# SF32LB58x register map
File version: 1.0
CPU: CM33 r0p1, little endian, MPU, FPU, 3 interrupt priority bits
Registers are 32-bit, read-write, reset 0x0 unless marked. A register's access mark holds for its fields unless they carry their own. Offsets are from the block's base; [hi:lo] are bit positions; 'fields as' and 'values as' point back to an identical list.

## DSI_HOST
Base 0x4001E000
0x00 VER
  [31:0] VALUE
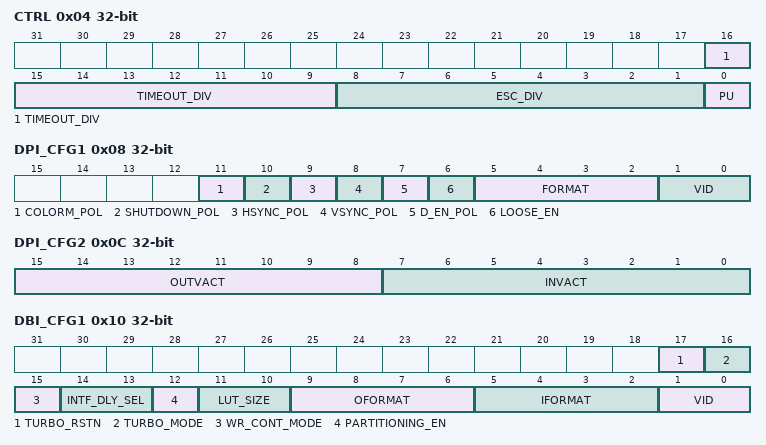
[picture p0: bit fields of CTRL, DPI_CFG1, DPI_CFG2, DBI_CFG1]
0x04 CTRL
  [16:9] TIMEOUT_DIV — Time out clock divider
  [8:1] ESC_DIV — tx escape clock divider
  [0] PU — 0: Reset 1: Power-up
0x08 DPI_CFG1
  [11] COLORM_POL — color mode polarity
  [10] SHUTDOWN_POL — shutdown polarity
  [9] HSYNC_POL — hsync polarity
  [8] VSYNC_POL — vsync polarity
  [7] D_EN_POL — data enable polarity
  [6] LOOSE_EN — enable loosely packed variant to 18-bit mode
  [5:2] FORMAT — dpi color format 4'b0000: 16-bit configuration 1 4'b0001: 16-bit configuration 2 4'b0010: 16-bit configuration 3 4'b0011: 18-bit configuration 1 4'b0100: 18-bit configuration 2 4'b0101: 24-bit 4'b0110: 20-bit YCbCr 4:2:2 loosely packed 4'b0111: 24-bit YCbCr 4:2:2 4'b1000: 16-bit YCbCr 4:2:2 4'b1001: 30-bit 4'b1010: 36-bit 4'b1011-1111: 12-bit YCbCr 4:2:0
  [1:0] VID — dpi channel id
0x0C DPI_CFG2
  [15:8] OUTVACT — command packet size in a line during VSA/VBP/VFP region
  [7:0] INVACT — command packet size in a line during VACT region
0x10 DBI_CFG1
  [17] TURBO_RSTN — dbi turbo mode engine resetn
  [16] TURBO_MODE — dbi turbo mode 1: turbo mode, dbi bandwidth can reach lanebyteclk*8 bps 0: normal mode
  [15] WR_CONT_MODE — dbi write memory continuous mode when internal auto partioning enable. 1: write memory continue command(0x3c) can initial data transfer. 0: write memory continue command(0x3c) cannot initial data transfer.
  [14:13] INTF_DLY_SEL — dbi interface data delay select 00: no delay 01: delay by half cycle 10,11: delay by one cycle
  [12] PARTITIONING_EN — external partitioning enable 1: external partitioning enable 0: internal auto partitioning enable
  [11:10] LUT_SIZE — LUT commands size 00,11: 16-bit color display 01: 18-bit color display 10: 24-bit color display
  [9:6] OFORMAT — DBI output pixel format 0000: 8-bit 8 bpp 0001: 8-bit 12 bpp 0010: 8-bit 16 bpp 0011: 8-bit 18 bpp 0100: 8-bit 24 bpp 0101: 9-bit 18 bpp 0110: 16-bit 8 bpp 0111: 16-bit 12 bpp 1000: 16-bit 16 bpp 1001: 16-bit 18 bpp, option 1 1010: 16-bit 18 bpp, option 2 1011: 16-bit 24 bpp, option 1 1100: 16-bit 24 bpp, option 2
  [5:2] IFORMAT — DBI input pixel format 0000: 8-bit 8 bpp 0001: 8-bit 12 bpp 0010: 8-bit 16 bpp 0011: 8-bit 18 bpp 0100: 8-bit 24 bpp 0101: 9-bit 18 bpp 0110: 16-bit 8 bpp 0111: 16-bit 12 bpp 1000: 16-bit 16 bpp 1001: 16-bit 18 bpp, option 1 1010: 16-bit 18 bpp, option 2 1011: 16-bit 24 bpp, option 1 1100: 16-bit 24 bpp, option 2
  [1:0] VID — DBI virtual channel id
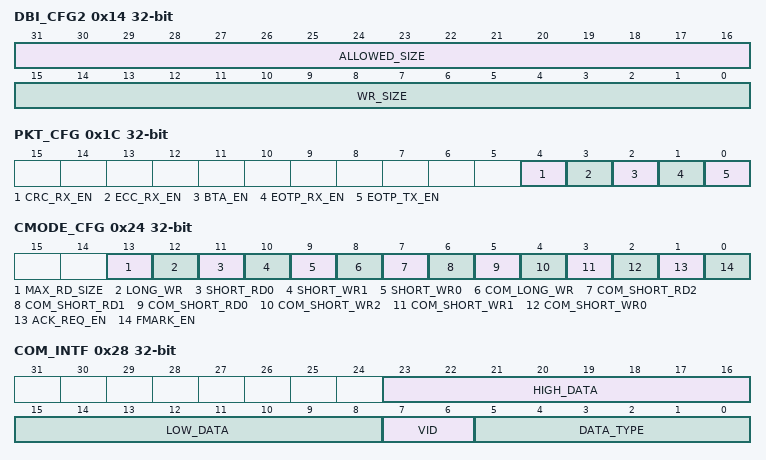
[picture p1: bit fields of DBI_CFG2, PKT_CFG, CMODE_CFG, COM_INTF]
0x14 DBI_CFG2
  [31:16] ALLOWED_SIZE — maximum allowed write memory data size. Used when partioning is enable.
  [15:0] WR_SIZE — write memory data size. DSI packet payload is the actual payload size minus 1
0x18 COM_CFG
  [1:0] VID — common interface virtual channel id
0x1C PKT_CFG
  [4] CRC_RX_EN — CRC reception enable
  [3] ECC_RX_EN — ECC reception enable
  [2] BTA_EN — bus turn around request
  [1] EOTP_RX_EN — EoTp reception
  [0] EOTP_TX_EN — EoTp transmission
0x20 MODE_CFG reset 0x1
  [0] CMD_VIDEO_SEL — 0: video mode 1: command mode
0x24 CMODE_CFG
  [13] MAX_RD_SIZE — maximum read packet size command transmission type 0: high-speed 1: low-power
  [12] LONG_WR — DCS long write packet command transmission type 0: high-speed 1: low-power
  [11] SHORT_RD0 — DCS short read packet with 0 parameter command transmission type 0: high-speed 1: low-power
  [10] SHORT_WR1 — DCS short write packet with 1 parameter command transmission type 0: high-speed 1: low-power
  [9] SHORT_WR0 — DCS short write packet with 0 parameter command transmission type 0: high-speed 1: low-power
  [8] COM_LONG_WR — generic long write packet command transmission type 0: high-speed 1: low-power
  [7] COM_SHORT_RD2 — common short read with 2 paramters command transmission type 0: high-speed 1: low-power
  [6] COM_SHORT_RD1 — common short read with 1 paramters command transmission type 0: high-speed 1: low-power
  [5] COM_SHORT_RD0 — common short read with 0 paramters command transmission type 0: high-speed 1: low-power
  [4] COM_SHORT_WR2 — common short write with 2 paramters command transmission type 0: high-speed 1: low-power
  [3] COM_SHORT_WR1 — common short write with 1 paramters command transmission type 0: high-speed 1: low-power
  [2] COM_SHORT_WR0 — common short write with 0 paramters command transmission type 0: high-speed 1: low-power
  [1] ACK_REQ_EN — acknowledge request enable
  [0] FMARK_EN — fmark enable
0x28 COM_INTF
  [23:16] HIGH_DATA — common interface MSB of header packet's word count of long packet or data 1 for short packets
  [15:8] LOW_DATA — common interface LSB of header packet's word count of long packet or data 0 for short packets
  [7:6] VID — common interface virtual channel id
  [5:0] DATA_TYPE — common interface packet data type
0x2C COM_PLD
  [31:0] PDATA — common interface payload data
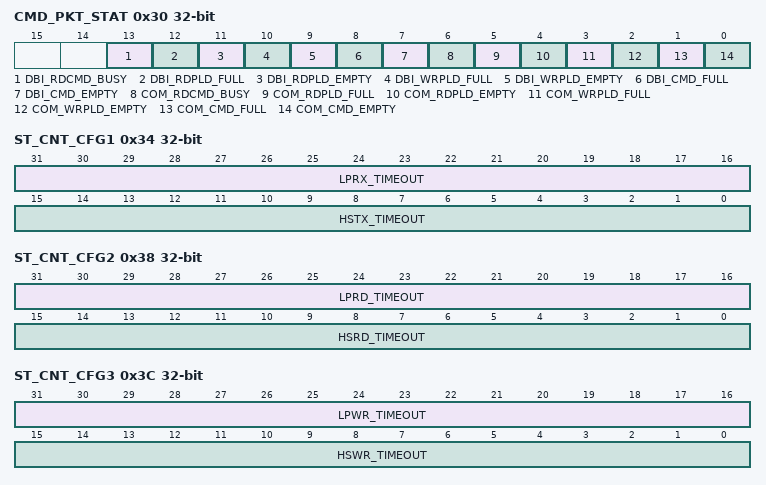
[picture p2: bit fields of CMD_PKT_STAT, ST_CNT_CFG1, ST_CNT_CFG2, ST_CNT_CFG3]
0x30 CMD_PKT_STAT
  [13] DBI_RDCMD_BUSY — DBI read command busy
  [12] DBI_RDPLD_FULL — DBI read payload FIFO full
  [11] DBI_RDPLD_EMPTY — DBI read payload FIFO empty
  [10] DBI_WRPLD_FULL — DBI write payload FIFO full
  [9] DBI_WRPLD_EMPTY — DBI write payload FIFO empty
  [8] DBI_CMD_FULL — DBI command FIFO full
  [7] DBI_CMD_EMPTY — DBI command FIFO empty
  [6] COM_RDCMD_BUSY — common read command busy
  [5] COM_RDPLD_FULL — common read payload FIFO full
  [4] COM_RDPLD_EMPTY — common read payload FIFO empty
  [3] COM_WRPLD_FULL — common write payload FIFO full
  [2] COM_WRPLD_EMPTY — common write payload FIFO empty
  [1] COM_CMD_FULL — common command FIFO full
  [0] COM_CMD_EMPTY — common command FIFO empty
0x34 ST_CNT_CFG1
  [31:16] LPRX_TIMEOUT — LPRX timeout counter
  [15:0] HSTX_TIMEOUT — HSTX timeout counter
0x38 ST_CNT_CFG2
  [31:16] LPRD_TIMEOUT — LP read timeout counter
  [15:0] HSRD_TIMEOUT — HS read timeout counter
0x3C ST_CNT_CFG3
  [31:16] LPWR_TIMEOUT — LP write timeout counter
  [15:0] HSWR_TIMEOUT — HS write timeout counter
0x40 ST_CNT_CFG4
  [15:0] BTA_TIMEOUT — BTA timeout counter
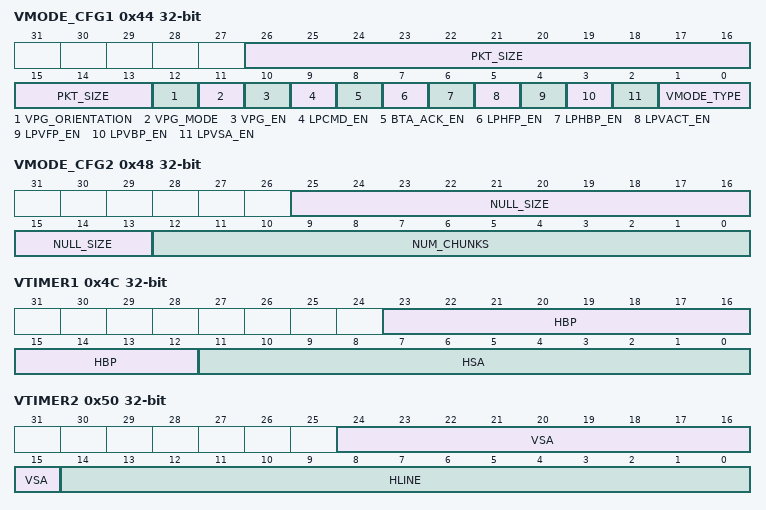
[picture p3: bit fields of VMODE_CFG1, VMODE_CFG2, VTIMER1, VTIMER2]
0x44 VMODE_CFG1
  [26:13] PKT_SIZE — Number of pixels in a single video packet
  [12] VPG_ORIENTATION — color bar orientation 0: vertical mode 1: horizontal mode
  [11] VPG_MODE — pattern 0: color bar 1: ber pattern
  [10] VPG_EN — video mode pattern generator enable
  [9] LPCMD_EN — enable command transmission only in lp mode
  [8] BTA_ACK_EN — enable request for an ack response
  [7] LPHFP_EN — enable return to lp inside HFP
  [6] LPHBP_EN — enable return to lp inside HBP
  [5] LPVACT_EN — enable return to lp inside VACT
  [4] LPVFP_EN — enable return to lp inside VFP
  [3] LPVBP_EN — enable return to lp inside VBP
  [2] LPVSA_EN — enable return to lp inside VSA
  [1:0] VMODE_TYPE — indicates video mode transmission type 00: Non-burst with sync pulses 01: Non-burst with sync events 10,11: Burst mode
0x48 VMODE_CFG2
  [25:13] NULL_SIZE — number of bytes inside a null packet
  [12:0] NUM_CHUNKS — number of chunks during a Line period
0x4C VTIMER1
  [23:12] HBP — HBP period
  [11:0] HSA — HSA period
0x50 VTIMER2
  [24:15] VSA — VSA lines
  [14:0] HLINE — HLINE period
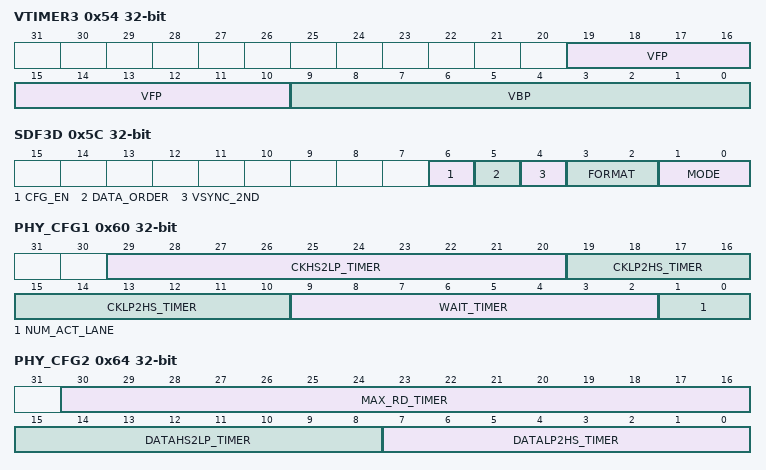
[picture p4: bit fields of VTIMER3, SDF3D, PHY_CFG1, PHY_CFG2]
0x54 VTIMER3
  [19:10] VFP — VFP lines
  [9:0] VBP — VBP lines
0x58 VTIMER4
  [13:0] VACT — VACTIVE lines
0x5C SDF3D
  [6] CFG_EN — transfer packet with 3D control payload
  [5] DATA_ORDER — data order 0: left eye data first 1: right eye data first
  [4] VSYNC_2ND — set sync between left and right image 0: no vsync pulse 1: add sync pulse
  [3:2] FORMAT — 3D image format 00: Line 01: Frame 10: Pixel 11: Reserved
  [1:0] MODE — 3D mode 00: 3D mode off 01: 3D mode on, portrait orientation 10: 3D mode on, landscape orientation 11: Reserved
0x60 PHY_CFG1
  [29:20] CKHS2LP_TIMER — CK lane HS to LP transition time
  [19:10] CKLP2HS_TIMER — CK lane LP to HS transition time
  [9:2] WAIT_TIMER — wait period between Stop State and HS
  [1:0] NUM_ACT_LANE — Number of active lanes 00: 1 data lane 01: 2 data lane 10,11: Reserved
0x64 PHY_CFG2
  [30:16] MAX_RD_TIMER — max read time
  [15:8] DATAHS2LP_TIMER — Data lane HS to LP transition time
  [7:0] DATALP2HS_TIMER — Data lane LP to HS transition time
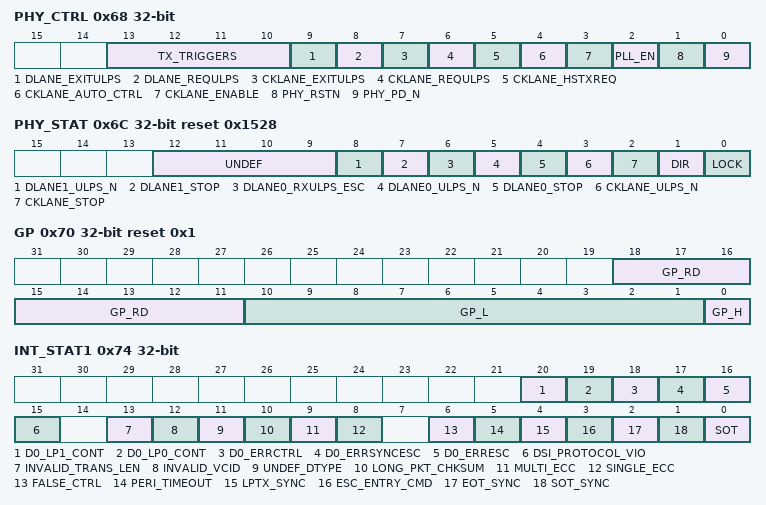
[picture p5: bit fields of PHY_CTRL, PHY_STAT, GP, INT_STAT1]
0x68 PHY_CTRL
  [13:10] TX_TRIGGERS — tx trigger transmission
  [9] DLANE_EXITULPS — ULPS exit for all data lane
  [8] DLANE_REQULPS — ULPS request for all data lane
  [7] CKLANE_EXITULPS — ULPS exit for ck lane
  [6] CKLANE_REQULPS — ULPS request for ck lane
  [5] CKLANE_HSTXREQ — hstx request for ck lane
  [4] CKLANE_AUTO_CTRL — ck lane auto on/off control
  [3] CKLANE_ENABLE
  [2] PLL_EN — pll enable
  [1] PHY_RSTN — D_PHY reset, active low
  [0] PHY_PD_N — D_PHY power down, active low
0x6C PHY_STAT reset 0x1528
  [12:9] UNDEF
  [8] DLANE1_ULPS_N — Data lane 1 ulps active not signal
  [7] DLANE1_STOP — Data lane 1 stop state signal
  [6] DLANE0_RXULPS_ESC — Data lane 0 rx ulps esc signal
  [5] DLANE0_ULPS_N — Data lane 0 ulps active not signal
  [4] DLANE0_STOP — Data lane 0 stop state signal
  [3] CKLANE_ULPS_N — CK lane ulps active not signal
  [2] CKLANE_STOP — CK lane stop state signal
  [1] DIR — phy direction
  [0] LOCK — phy lock
0x70 GP reset 0x1
  [18:11] GP_RD, [10:1] GP_L, [0] GP_H
0x74 INT_STAT1
  [20] D0_LP1_CONT — dlane0 LP1 contention error
  [19] D0_LP0_CONT — dlane0 LP0 contention error
  [18] D0_ERRCTRL — dlane0 ErrControl error
  [17] D0_ERRSYNCESC — dlane0 ErrSyncEsc lpdt synchronization error
  [16] D0_ERRESC — dlane0 ErrEsc escape entry error
  [15] DSI_PROTOCOL_VIO — DSI protocol violation
  [13] INVALID_TRANS_LEN — invalid transmission length
  [12] INVALID_VCID — invalid DSI VC ID
  [11] UNDEF_DTYPE — undefined DSI data type error
  [10] LONG_PKT_CHKSUM — long packet checksum error
  [9] MULTI_ECC — multi-bit ECC error for ack report
  [8] SINGLE_ECC — single-bit ECC error for ack report
  [6] FALSE_CTRL — False Control error
  [5] PERI_TIMEOUT — Peripheral Timeout error
  [4] LPTX_SYNC — LP Transmit Sync error
  [3] ESC_ENTRY_CMD — ESC Mode Entry Command error
  [2] EOT_SYNC — EoT Sync error
  [1] SOT_SYNC — SoT Sync error
  [0] SOT — SoT error
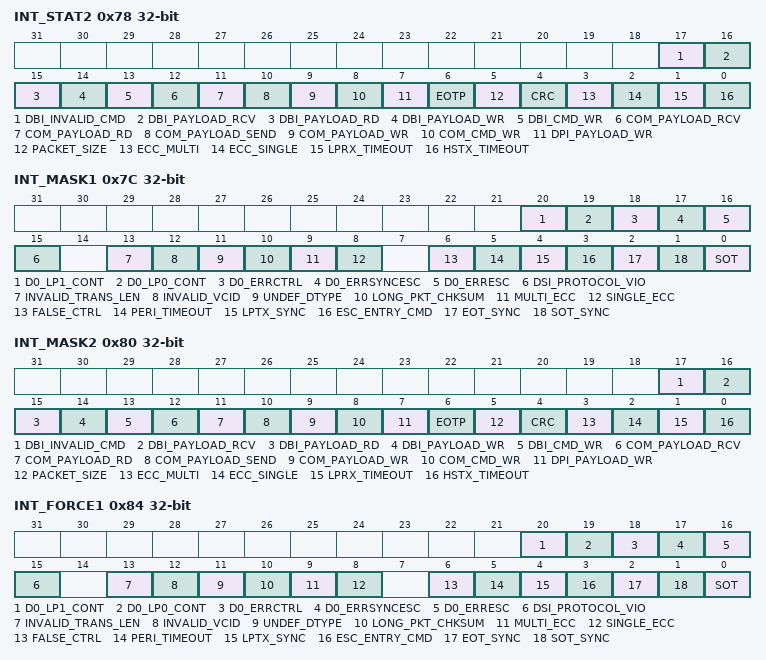
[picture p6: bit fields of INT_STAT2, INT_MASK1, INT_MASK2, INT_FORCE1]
0x78 INT_STAT2
  [17] DBI_INVALID_CMD — dbi invalid command error
  [16] DBI_PAYLOAD_RCV — dbi payload FIFO overflow during packet read back
  [15] DBI_PAYLOAD_RD — dbi payload FIFO underflow during DCS read data
  [14] DBI_PAYLOAD_WR — dbi payload FIFO overflow during data write
  [13] DBI_CMD_WR — dbi command FIFO overflow during command write
  [12] COM_PAYLOAD_RCV — common interface payload FIFO overflow during packet read back
  [11] COM_PAYLOAD_RD — common interface payload FIFO underflow during DCS read data
  [10] COM_PAYLOAD_SEND — common interface payload FIFO underflow during packet build
  [9] COM_PAYLOAD_WR — common interface payload FIFO overflow during data write
  [8] COM_CMD_WR — common interface command FIFO overflow during command write
  [7] DPI_PAYLOAD_WR — dpi payload FIFO overflow
  [6] EOTP — EoTp packet is not received
  [5] PACKET_SIZE — packet size error
  [4] CRC — CRC error in received packet
  [3] ECC_MULTI — ECC multiple error in received packet
  [2] ECC_SINGLE — ECC single error in received packet
  [1] LPRX_TIMEOUT
  [0] HSTX_TIMEOUT
0x7C INT_MASK1
  [20] D0_LP1_CONT, [19] D0_LP0_CONT, [18] D0_ERRCTRL, [17] D0_ERRSYNCESC, [16] D0_ERRESC, [15] DSI_PROTOCOL_VIO, [13] INVALID_TRANS_LEN, [12] INVALID_VCID, [11] UNDEF_DTYPE, [10] LONG_PKT_CHKSUM, [9] MULTI_ECC, [8] SINGLE_ECC, [6] FALSE_CTRL, [5] PERI_TIMEOUT, [4] LPTX_SYNC, [3] ESC_ENTRY_CMD, [2] EOT_SYNC, [1] SOT_SYNC, [0] SOT
0x80 INT_MASK2
  [17] DBI_INVALID_CMD, [16] DBI_PAYLOAD_RCV, [15] DBI_PAYLOAD_RD, [14] DBI_PAYLOAD_WR, [13] DBI_CMD_WR, [12] COM_PAYLOAD_RCV, [11] COM_PAYLOAD_RD, [10] COM_PAYLOAD_SEND, [9] COM_PAYLOAD_WR, [8] COM_CMD_WR, [7] DPI_PAYLOAD_WR, [6] EOTP, [5] PACKET_SIZE, [4] CRC, [3] ECC_MULTI, [2] ECC_SINGLE, [1] LPRX_TIMEOUT, [0] HSTX_TIMEOUT
0x84 INT_FORCE1
  fields as INT_MASK1
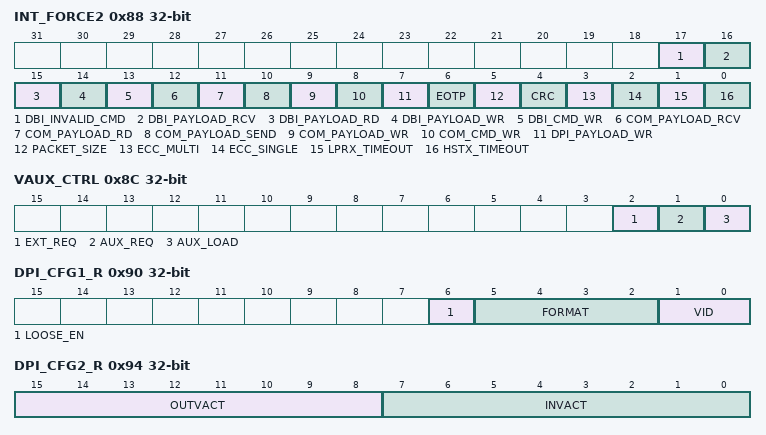
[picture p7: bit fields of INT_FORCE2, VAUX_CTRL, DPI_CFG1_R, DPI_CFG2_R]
0x88 INT_FORCE2
  fields as INT_MASK2
0x8C VAUX_CTRL
  [2] EXT_REQ — When set to 1, the video request is done by external pin. In this mode, aux_req is ignored.
  [1] AUX_REQ — When set to 1, the DPI registers are copied to the auxiliary registers. After copying, this bit is auto cleared.
  [0] AUX_LOAD — When set to 1, DPI receives the active configuration from the auxiliary registers. When this bit is set along with the aux_req bit, the auxiliary registers are automatically updated.
0x90 DPI_CFG1_R
  [6] LOOSE_EN — enable loosely packed variant to 18-bit mode
  [5:2] FORMAT — dpi color format
  [1:0] VID — dpi channel id
0x94 DPI_CFG2_R
  fields as DPI_CFG2
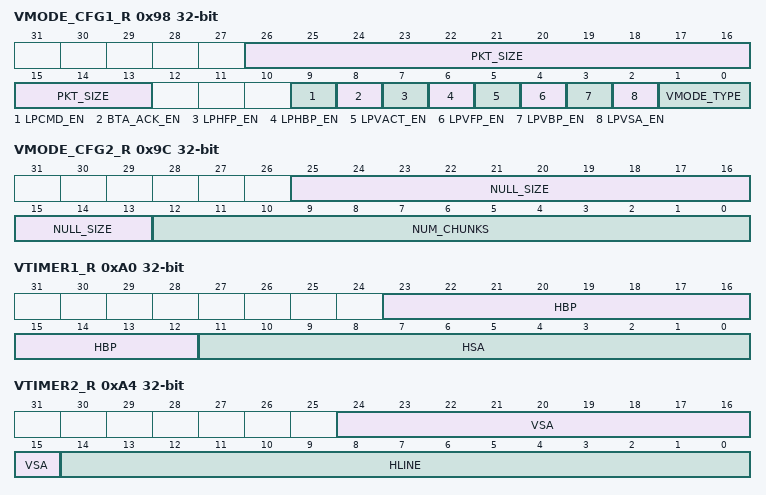
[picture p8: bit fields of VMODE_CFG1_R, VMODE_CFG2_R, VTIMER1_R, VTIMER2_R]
0x98 VMODE_CFG1_R
  [26:13] PKT_SIZE — Number of pixels in a single video packet
  [9] LPCMD_EN — enable command transmission only in lp mode
  [8] BTA_ACK_EN — enable request for an ack response
  [7] LPHFP_EN — enable return to lp inside HFP
  [6] LPHBP_EN — enable return to lp inside HBP
  [5] LPVACT_EN — enable return to lp inside VACT
  [4] LPVFP_EN — enable return to lp inside VFP
  [3] LPVBP_EN — enable return to lp inside VBP
  [2] LPVSA_EN — enable return to lp inside VSA
  [1:0] VMODE_TYPE — indicates video mode transmission type 00: Non-burst with sync pulses 01: Non-burst with sync events 10,11: Burst mode
0x9C VMODE_CFG2_R
  fields as VMODE_CFG2
0xA0 VTIMER1_R
  [23:12] HBP — HBP period
  [11:0] HSA — HSA period
0xA4 VTIMER2_R
  [24:15] VSA — VSA lines
  [14:0] HLINE — HLINE period
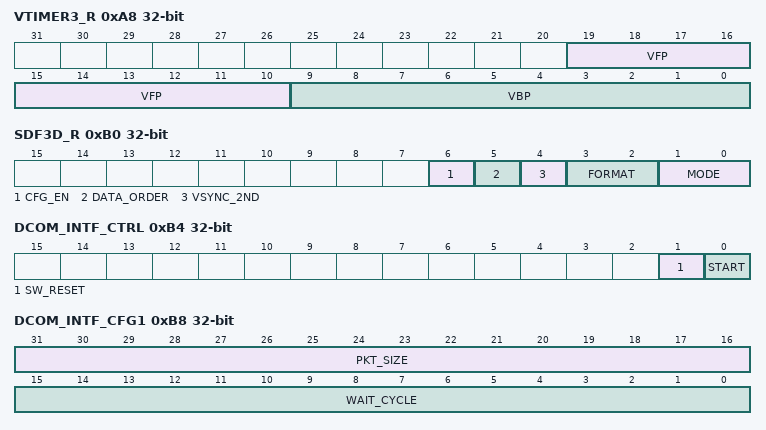
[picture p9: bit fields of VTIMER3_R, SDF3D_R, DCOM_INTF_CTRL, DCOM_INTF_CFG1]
0xA8 VTIMER3_R
  [19:10] VFP — VFP lines
  [9:0] VBP — VBP lines
0xAC VTIMER4_R
  [13:0] VACT — VACTIVE lines
0xB0 SDF3D_R
  fields as SDF3D
0xB4 DCOM_INTF_CTRL
  [1] SW_RESET — software reset for direct common interface
  [0] START — start direct common interface
0xB8 DCOM_INTF_CFG1
  [31:16] PKT_SIZE — direct common interface packet size(bytes)
  [15:0] WAIT_CYCLE — wait period after each packet
0xBC DCOM_INTF_CFG2
  [31:0] TOTAL_SIZE — total pixel size(bytes)
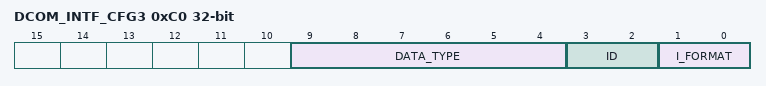
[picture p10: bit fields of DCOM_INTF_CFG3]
0xC0 DCOM_INTF_CFG3
  [9:4] DATA_TYPE — direct common interface command data type
  [3:2] ID — direct common interface command virtual id
  [1:0] I_FORMAT — input pixel format 0: RGB565 1: RGB888 2: ARGB8888 3: RGB332
